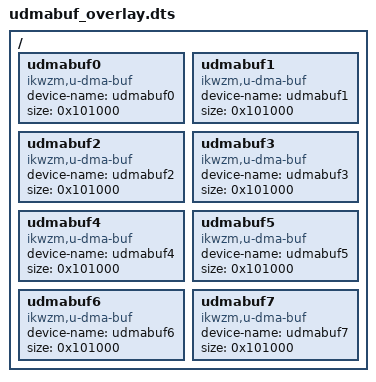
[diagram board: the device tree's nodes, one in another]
/dts-v1/;
/plugin/;

// u-dma-buf frame buffers for the phase-correlation pipeline (ikwzm u-dma-buf).
// Eight buffers sized 0x101000 (1 MiB + 4 KiB = 1,052,672 B) each.
// N=256: frame = 256*256*16 = 1,048,576 B + 2 prefix beats*16 = 1,048,608 B < 0x101000.
// UioBackend assigns roles (samples, F, G, R, P, corr, scratch).
// Independent of the FPGA overlay; needs CMA >= ~8.5 MiB.

/ {
    fragment@0 {
        target-path = "/";
        __overlay__ {
            udmabuf0 { compatible = "ikwzm,u-dma-buf"; device-name = "udmabuf0"; size = <0x101000>; };
            udmabuf1 { compatible = "ikwzm,u-dma-buf"; device-name = "udmabuf1"; size = <0x101000>; };
            udmabuf2 { compatible = "ikwzm,u-dma-buf"; device-name = "udmabuf2"; size = <0x101000>; };
            udmabuf3 { compatible = "ikwzm,u-dma-buf"; device-name = "udmabuf3"; size = <0x101000>; };
            udmabuf4 { compatible = "ikwzm,u-dma-buf"; device-name = "udmabuf4"; size = <0x101000>; };
            udmabuf5 { compatible = "ikwzm,u-dma-buf"; device-name = "udmabuf5"; size = <0x101000>; };
            udmabuf6 { compatible = "ikwzm,u-dma-buf"; device-name = "udmabuf6"; size = <0x101000>; };
            udmabuf7 { compatible = "ikwzm,u-dma-buf"; device-name = "udmabuf7"; size = <0x101000>; };
        };
    };
};
